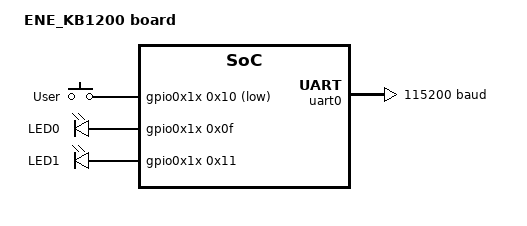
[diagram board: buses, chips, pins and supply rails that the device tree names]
/*
 * Copyright (c) ENE
 *
 * SPDX-License-Identifier: Apache-2.0
 */

/dts-v1/;


#include <ene_kb1200/ene_kb1200.dtsi>

/ {
	model = "ENE_KB1200 board";
	compatible = "ene,kb1200";

	aliases {
		uart0 = &uart0;
		led0 = &led0;
		led1 = &led1;
		sw0 = &user_button;
	};

	chosen {
		zephyr,sram = &sram0;
		zephyr,flash = &flash0;
		zephyr,console = &uart0;
		zephyr,shell-uart = &uart0;
	};

	gpio_keys {
		compatible = "gpio-keys";
		user_button: button {
			label = "User";
			gpios = <&gpio0x1x 0x10 (GPIO_ACTIVE_LOW | GPIO_PULL_UP)>;
		};
	};

	leds {
		compatible = "gpio-leds";
		/* green led */
		led0: led_0 {
			gpios = <&gpio0x1x 0x0f GPIO_ACTIVE_HIGH>;
			label = "LED0";
		};
		/* blue led */
		led1: led_1 {
			gpios = <&gpio0x1x 0x11 GPIO_ACTIVE_HIGH>;
			label = "LED1";
		};
	};

};

&uart0 {
	status = "okay";
	current-speed = <115200>;
};

&gpio0x1x {
	status = "okay";
};

